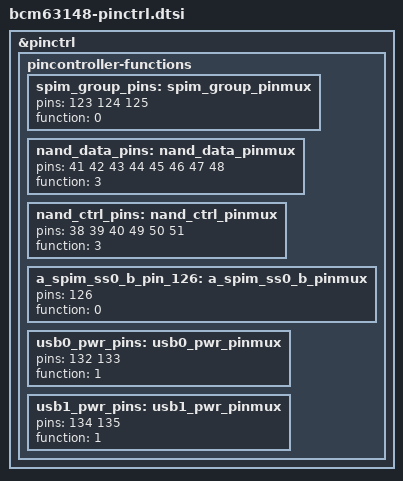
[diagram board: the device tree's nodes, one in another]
&pinctrl {
	pincontroller-functions {
		spim_group_pins: spim_group_pinmux {
			pins = <123 124 125>;
			function = <0>;
		};

		nand_data_pins: nand_data_pinmux {
			pins = <41 42 43 44 45 46 47 48>;
			function = <3>;
		};

		nand_ctrl_pins: nand_ctrl_pinmux {
			pins = <38 39 40 49 50 51>;
			function = <3>;
		};

		a_spim_ss0_b_pin_126: a_spim_ss0_b_pinmux {
			pins = <126>;
			function = <0>;
		};

		usb0_pwr_pins: usb0_pwr_pinmux {
			pins = <132 133>;
			function = <1>;
		};

		usb1_pwr_pins: usb1_pwr_pinmux {
			pins = <134 135>;
			function = <1>;
		};
	};
};
